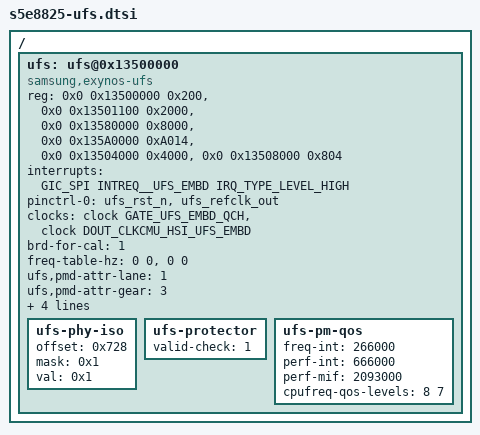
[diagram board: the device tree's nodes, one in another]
// SPDX-License-Identifier: GPL-2.0-only
//
// Samsung's SoC UFS device tree source
//
// Copyright (C) 2020 Samsung Electronics Co., Ltd.

//#include <dt-bindings/ufs/ufs.h>

/ {
	ufs: ufs@0x13500000 {
		/* ----------------------- */
		/* 1. SYSTEM CONFIGURATION */
		/* ----------------------- */
		compatible ="samsung,exynos-ufs";
		#address-cells = <2>;
		#size-cells = <1>;
		ranges;

		reg =
			<0x0 0x13500000 0x200>,	/* 0: HCI standard */
			<0x0 0x13501100 0x2000>, /* 1: Vendor specificed */
			<0x0 0x13580000 0x8000>,/* 2: UNIPRO */
			<0x0 0x135A0000 0xA014>,/* 3: UFS protector */
                        <0x0 0x13504000 0x4000>,	/* phy */
			<0x0 0x13508000 0x804>;	/* 6: CPORT */
		interrupts = <GIC_SPI INTREQ__UFS_EMBD IRQ_TYPE_LEVEL_HIGH>;
		pinctrl-names = "default";
		pinctrl-0 = <&ufs_rst_n &ufs_refclk_out>;
		clocks =
			/* aclk clock */
			<&clock GATE_UFS_EMBD_QCH>,
			/* unipro clocks */
			<&clock DOUT_CLKCMU_HSI_UFS_EMBD>;

		clock-names =
			/* aclk clocks */
			"GATE_UFS_EMBD",
			/* unipro clocks */
			"UFS_EMBD";

		/* board type for UFS CAL */
		brd-for-cal = /bits/ 8 <1>;  /* (1:SMDK, 16:UNIV) board */

		/* ----------------------- */
		/* 2. UFS COMMON           */
		/* ----------------------- */
		freq-table-hz = <0 0>, <0 0>;

//		vcc-supply = <&ufs_fixed_vcc>;
//		vcc-fixed-regulator;

		/* ----------------------- */
		/* 3. UFS EXYNOS           */
		/* ----------------------- */

		/* power mode change */
		ufs,pmd-attr-lane = /bits/ 8 <1>;
		ufs,pmd-attr-gear = /bits/ 8 <3>;

                /* evt version for UFS CAL */
		evt-ver = /bits/ 8 <0>;

		/* DMA coherent callback, should be coupled with 'ufs-sys' */
		//dma-coherent;
		/* UFS PHY isolation and TCXO control */
		samsung,pmu-phandle = <&pmu_system_controller>;
		/* UFS quirk managing flags */
		fixed-prdt-req_list-ocs;
		support-extended-features;

		/* ----------------------- */
		/* 4. ADDITIONAL NODES     */
		/* ----------------------- */
		ufs-phy-iso {
			offset = <0x728>;
			mask = <0x1>; /* (UFS_BIT(0)) */
			val = <0x1>;
		};

		ufs-protector {
			/* fmp hw status */
			valid-check = /bits/ 8 <1>;
		};

		ufs-pm-qos {
			freq-int = <266000>;
			perf-int = <666000>;
			perf-mif = <2093000>;
			cpufreq-qos-levels = <8 7>; /* 1690000 1690000 */
		};
	};

	/*ufs_fixed_vcc: fixedregulator@0 {
		       compatible = "regulator-fixed";
		       regulator-name = "ufs-vcc";
		       gpio = <&gpg2 0 0>;
		       enable-active-high;
	};*/
};
